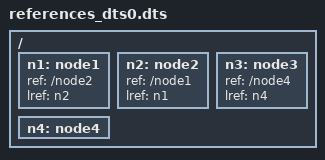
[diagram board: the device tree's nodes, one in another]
/ {
	/* Explicit phandles */
	n1: node1 {
		linux,phandle = <2000>;
		ref = <&/node2>; /* reference precedes target */
		lref = <&n2>;
	};
	n2: node2 {
		linux,phandle = <1>;
		ref = <&/node1>; /* reference after target */
		lref = <&n1>;
	};

	/* Implicit phandles */
	n3: node3 {
		ref = <&/node4>;
		lref = <&n4>;
	};
	n4: node4 {
	};
};
